# GBA register map
File version: 0.5
Registers are 16-bit, read-write, reset 0x0 unless marked. A register's access mark holds for its fields unless they carry their own. Offsets are from the block's base; [hi:lo] are bit positions; lines under a group give offsets from that group; {n}, {i} and the like mark numbered series.

## LCD — LCD I/O Registers
Base 0x04000000
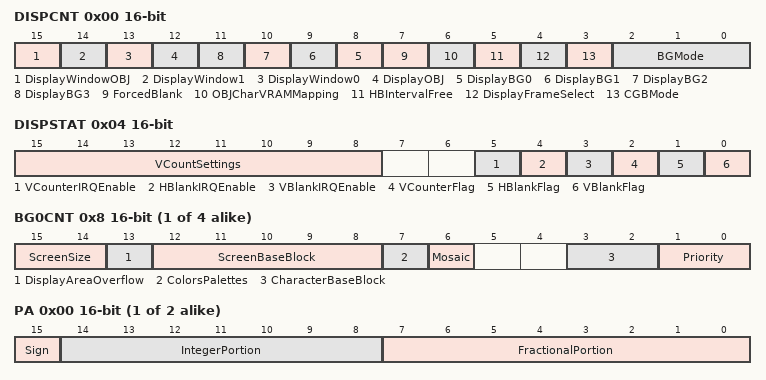
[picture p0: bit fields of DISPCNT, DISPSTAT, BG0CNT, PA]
0x00 DISPCNT — LCD I/O Display Control
  [15] DisplayWindowOBJ — If set to 1, displays Window Objects
  [14] DisplayWindow1 — If set to 1, displays Window 1
  [13] DisplayWindow0 — If set to 1, displays Window 0
  [12] DisplayOBJ — If set to 1, displays Objects
  [n+8] DisplayBG{n} (n=0..3) — If set to 1, displays Background {n}
  [7] ForcedBlank — If set to 1, allows FAST access to VRAM, Palette, OAM
  [6] OBJCharVRAMMapping — OBJ Character VRAM Mapping
    0=TwoDimension (One dimensional array); 1=OneDimension (Two dimensional array)
  [5] HBIntervalFree — Allow access to OAM during H-Blank
  [4] DisplayFrameSelect — Display Frame Select for only Background Mode 4/5
  [3] CGBMode ro — Check if CGB or AGB mode
  [2:0] BGMode — Background Mode
    0=Mode0 (0 No 0123 256x256..512x515 1024 16/16..256/1 SFMABP); 1=Mode1 (1 Mixed 012- (BG0,BG1 as above Mode 0, BG2 as below Mode 2)); 2=Mode2 (2 Yes --23 128x128..1024x1024 256 256/1 S-MABP); 3=Mode3 (3 Yes --2- 240x160 1 32768 --MABP); 4=Mode4 (4 Yes --2- 240x160 2 256/1 --MABP); 5=Mode5 (5 Yes --2- 160x128 2 32768 --MABP)
0x04 DISPSTAT — LCD I/O Interrupts
  [15:8] VCountSettings — The V-Count-Setting value is much the same as LYC of older gameboys, when its value is identical to the content of the VCOUNT register then the V-Counter flag is set (Bit 2), and (if enabled in Bit 5) an interrupt is requested.
  [5] VCounterIRQEnable — VCounter IRQ Enable Flag
  [4] HBlankIRQEnable — HBlank IRQ Enable Flag
  [3] VBlankIRQEnable — VBlank IRQ Enable Flag
  [2] VCounterFlag ro — VCounter Status Flag
  [1] HBlankFlag ro — HBlank Status Flag
  [0] VBlankFlag ro — VBlank Status Flag
0x06 VCOUNT ro — LCD VCount Status
  [7:0] LY — Current Scanline
{0x8+2i} BG{i}CNT (i=0..3) — BG{i} Control
  [15:14] ScreenSize — Sets the Screen Size
    0=Small (Text Mode: 256x256 (2K) | Rotation/Scaling Mode: 128x128 (256 bytes)); 1=Medium (Text Mode: 512x256 (4K) | Rotation/Scaling Mode: 256x256 (1K)); 2=High (Text Mode: 256x512 (4K) | Rotation/Scaling Mode: 512x512 (4K)); 3=Large (Text Mode: 512x512 (8K) | Rotation/Scaling Mode: 1024x1024 (16K))
  [13] DisplayAreaOverflow — How is Background displayed when Viewport reaches out this Background (only for Background 2/3)
    0=Transparent (Background becomes transparent); 1=Wraparound (Background will wrap around)
  [12:8] ScreenBaseBlock — Set BG Map data in units of 2KB
  [7] ColorsPalettes — Set Palettes or Color Types
    0=Limited (16 colors in 16 arrays); 1=Full (256 colors in one array)
  [6] Mosaic
  [3:2] CharacterBaseBlock — Set BG Tile date in units of 16KB
  [1:0] Priority — Set Priority of this Background
    0=Highest; 1=High; 2=Normal; 3=Low
{0x10+4i} BG{i}OFS (i=0..3) group — Set Background {i} Offset
  0x00 H wo — Horizontal Offset
    [8:0] Offset — Set the Horizontal Offset of this Background
  0x02 V wo — Vertical Offset
    [8:0] Offset — Set the Vertical Offset of this Background
{0x0+0x10*i} BG{i}ROTSCAL (i=2..3) group — Set Background {i} Offset
  0x00 PA wo — BG Rotation/Scaling Parameter A (alias dx)
    [15] Sign, [14:8] IntegerPortion, [7:0] FractionalPortion
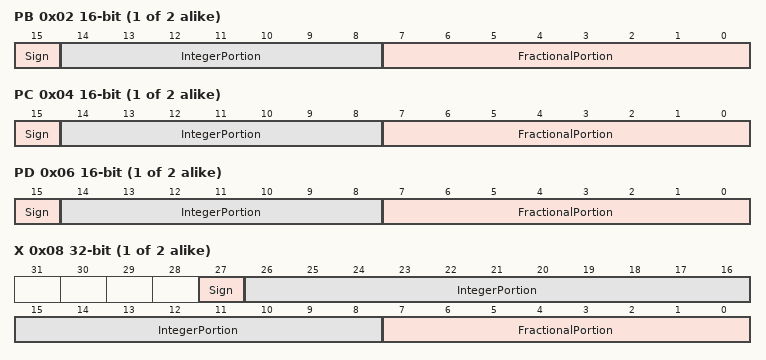
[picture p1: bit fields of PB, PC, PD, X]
  0x02 PB wo — BG Rotation/Scaling Parameter B (alias dmx)
    [15] Sign, [14:8] IntegerPortion, [7:0] FractionalPortion
  0x04 PC wo — BG Rotation/Scaling Parameter C (alias dy)
    [15] Sign, [14:8] IntegerPortion, [7:0] FractionalPortion
  0x06 PD wo — BG Rotation/Scaling Parameter D (alias dmy)
    [15] Sign, [14:8] IntegerPortion, [7:0] FractionalPortion
  0x08 X 32-bit wo — BG Reference Point X-Coordinate
    [27] Sign, [26:8] IntegerPortion, [7:0] FractionalPortion
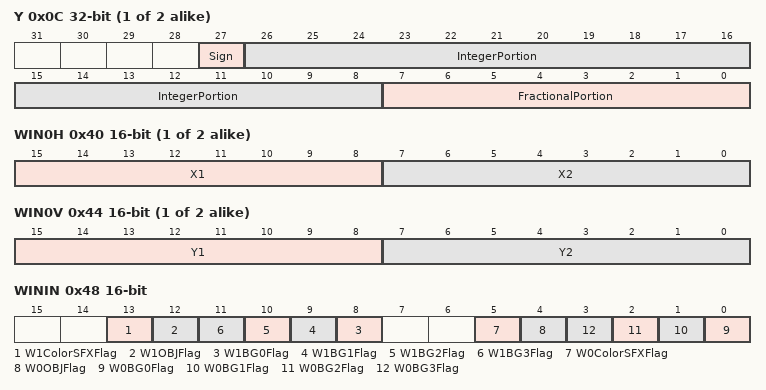
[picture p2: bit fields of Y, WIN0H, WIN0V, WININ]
  0x0C Y 32-bit wo — BG Reference Point Y-Coordinate
    [27] Sign, [26:8] IntegerPortion, [7:0] FractionalPortion
{0x40+2i} WIN{i}H (i=0..1) wo — Window {i} Horizontal Dimensions
  [15:8] X1 — Leftmost coordinate of window
  [7:0] X2 — Rightmost coordinate of window, plus 1
{0x44+2i} WIN{i}V (i=0..1) wo — Window {i} Vertical Dimensions
  [15:8] Y1 — Top-most coordinate of window
  [7:0] Y2 — Bottom-most coordinate of window, plus 1
0x48 WININ — Control of Inside of Window(s)
  [13] W1ColorSFXFlag — Window 1 Color Special Effect
  [12] W1OBJFlag — Window 1 OBJ Enable Bit
  [n+8] W1BG{n}Flag (n=0..3) — Window 1 BG{n} Enable Bit
  [5] W0ColorSFXFlag — Window 0 Color Special Effect
  [4] W0OBJFlag — Window 0 OBJ Enable Bit
  [n] W0BG{n}Flag (n=0..3) — Window 0 BG{n} Enable Bit
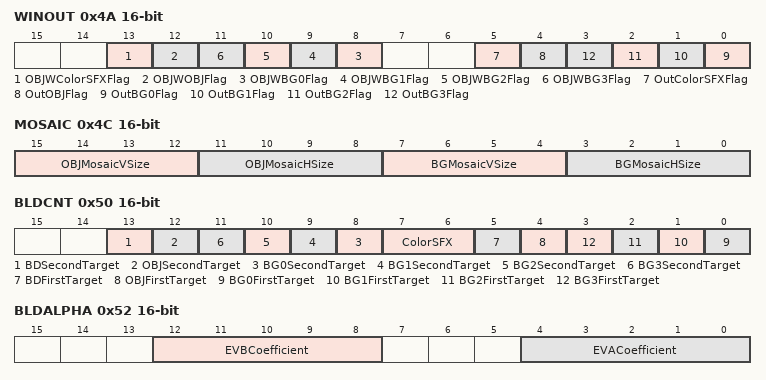
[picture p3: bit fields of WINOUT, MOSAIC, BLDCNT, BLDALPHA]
0x4A WINOUT — Control of Outside of Windows And Inside of OBJ Window
  [13] OBJWColorSFXFlag — OBJ Window Color Special Effect
  [12] OBJWOBJFlag — OBJ Window OBJ Enable Bit
  [n+8] OBJWBG{n}Flag (n=0..3) — OBJ Window BG{n} Enable Bit
  [5] OutColorSFXFlag — Outside Color Special Effect
  [4] OutOBJFlag — Outside OBJ Enable Bit
  [n] OutBG{n}Flag (n=0..3) — Outside BG{n} Enable Bit
0x4C MOSAIC wo — Mosaic Size
  [15:12] OBJMosaicVSize — OBJ Mosaic V-Size (minus 1)
  [11:8] OBJMosaicHSize — OBJ Mosaic H-Size (minus 1)
  [7:4] BGMosaicVSize — BG Mosaic V-Size (minus 1)
  [3:0] BGMosaicHSize — BG Mosaic H-Size (minus 1)
0x50 BLDCNT — Color Special Effects Selection
  [13] BDSecondTarget — BD 2nd Target Pixel (Backdrop)
  [12] OBJSecondTarget — OBJ 2nd Target Pixel (Top-most OBJ pixel)
  [n+8] BG{n}SecondTarget (n=0..3) — BG{n} 2nd Target Pixel (Background {n})
  [7:6] ColorSFX — Color Special Effect
    0=None (Special effects disabled); 1=AlphaBlending (1st+2nd Target mixed); 2=BrightnessIncrease (1st Target becomes whiter); 3=BrightnessDecrease (1st Target becomes blacker)
  [5] BDFirstTarget — BD 1st Target Pixel (Backdrop)
  [4] OBJFirstTarget — OBJ 1st Target Pixel (Top-most OBJ pixel)
  [n] BG{n}FirstTarget (n=0..3) — BG{n} 1st Target Pixel (Background {n})
0x52 BLDALPHA wo — Alpha Blending Coefficient
  [12:8] EVBCoefficient — EVB Coefficient (2nd Target) (0..16 = 0/16..16/16, 17..31=16/16)
  [4:0] EVACoefficient — EVA Coefficient (1st Target) (0..16 = 0/16..16/16, 17..31=16/16)
0x54 BLDY wo — Brightness (Fade-In/Out) Coefficient
  [4:0] EVYCoefficient — EVY Coefficient (Brightness) (0..16 = 0/16..16/16, 17..31=16/16)
